# ballast register map
Vendor: tuni.fi; File version: 1.0
CPU: other r1p0, little endian, MPU, no FPU, vendor SysTick, 3 interrupt priority bits
Registers are 32-bit, read-only, no defined reset value unless marked. A register's access mark holds for its fields unless they carry their own. Offsets are from the block's base; [hi:lo] are bit positions; lines under a group give offsets from that group.

## ethernet
Base 0x0E000000
0x00 MAC_registers group
  0x00 Tx_Hwmark rw reset 0x9 (reset mask 0x0) — used to set transmit Fifo high water mark
    [4:0] Tx_Hwmark
  0x04 Tx_Lwmark rw reset 0x8 (reset mask 0x0) — used to set transmit Fifo low water mark
    [4:0] Tx_Lwmark
  0x08 pause_frame_send_en rw — pause_frame_send_en register is used to enable transmit logic to send PAUSE frame.
    [0] pause_frame_send_en
  0x0C pause_quanta_set rw — pause_quanta_set register is used to setting quanta value in send PAUSE frame.
    [15:0] pause_quanta_set
  0x10 IFGset rw reset 0xC (reset mask 0x0) — RX_IFG_SET is used to set received frame gap. If the gap between two received packets is less than RX_IFG_SET,the second packet will be drop as an invalid frame.
    [5:0] IFGset
  0x14 FullDuplex rw reset 0x1 (reset mask 0x0) — This config register is only used in 100Mbps and 10Mbps. When FullDuplex register is equal to “1” , the transmit state machine will be FullDuplex mode. Otherwise, the transmit state machine will detect collision ,perform random slot time back off , retransmit collision packet and some other half-duplex operations.
    [0] FullDuplex
  0x18 MaxRetry rw reset 0x2 (reset mask 0x0) — When collision occurred in half duplex mode, the transmit state machine will try to transmit this collision packet again. If one packet collide MaxRetry times, this packet will be drop and never try again.
    [3:0] MaxRetry
  0x1C MAC_tx_add_en rw — Those registers are used to set mac address which will replace the target mac address of transmit packet. This function will be enable one when register MAC_tx_add_en set to “1”. At the rising edge of signal MAC_tx_add_prom_wr, the value of MAC_tx_add_prom_data will be write to prom address MAC_tx_add_prom_add. You need repeat six times to write six bytes length target mac to prom.
    [0] MAC_tx_add_en
  0x20 MAC_tx_add_prom_data rw — Those registers are used to set mac address which will replace the target mac address of transmit packet. This function will be enable one when register MAC_tx_add_en set to “1”. At the rising edge of signal MAC_tx_add_prom_wr, the value of MAC_tx_add_prom_data will be write to prom address MAC_tx_add_prom_add. You need repeat six times to write six bytes length target mac to prom.
    [7:0] MAC_tx_add_prom_data
  0x24 MAC_tx_add_prom_add rw — Those registers are used to set mac address which will replace the target mac address of transmit packet. This function will be enable one when register MAC_tx_add_en set to “1”. At the rising edge of signal MAC_tx_add_prom_wr, the value of MAC_tx_add_prom_data will be write to prom address MAC_tx_add_prom_add. You need repeat six times to write six bytes length target mac to prom.
    [2:0] MAC_tx_add_prom_add
  0x28 MAC_tx_add_prom_wr rw — Those registers are used to set mac address which will replace the target mac address of transmit packet. This function will be enable one when register MAC_tx_add_en set to “1”. At the rising edge of signal MAC_tx_add_prom_wr, the value of MAC_tx_add_prom_data will be write to prom address MAC_tx_add_prom_add. You need repeat six times to write six bytes length target mac to prom.
    [0] MAC_tx_add_prom_wr
  0x2C tx_pause_en rw — When this register is “1”, this core will respond to received pause frame.The transmit state machine will enter PAUSE state according to quanta value in received packet . One quanta time is equal to the time of transmit 512bit data.
    [0] tx_pause_en
  0x30 xoff_cpu rw — The rising pulse of xoff_cpu signal is used to start transmit one PAUSE frame when the transmit in idle state with quanta zero, asking remote ethernet controller jump out from pause state.
    [0] xoff_cpu
  0x34 xon_cpu rw — The rising pulse of xon_cpu signal is used to start transmit one PAUSE frame with quanta value of pause_quanta_set when the transmit in idle state.
    [0] xon_cpu
  0x38 MAC_rx_add_chk_en rw
    [0] MAC_rx_add_chk_en
  0x3C MAC_rx_add_prom_data rw
    [7:0] MAC_rx_add_prom_data
  0x40 MAC_rx_add_prom_add rw
    [2:0] MAC_rx_add_prom_add
  0x44 MAC_rx_add_prom_wr rw
    [0] MAC_rx_add_prom_wr
  0x48 broadcast_filter_en rw — The broadcast packet filter will enable only when broadcast_filter_en is set
    [0] broadcast_filter_en
  0x4C broadcast_bucket_depth rw — broadcast_bucket_depth register is used to setting the bucket depth
    [15:0] broadcast_bucket_depth
  0x50 broadcast_bucket_interval rw — The bucket wil be periodically refilled after broadcast_bucket_interval time
    [15:0] broadcast_bucket_interval
  0x54 RX_APPEND_CRC rw — In some condition, the user application need MAC to retain FCS of ethernet frame. When RX_APPEND_CRC signal is equal “1” , the FCS of ethernet frame will transmit to user application.
    [0] RX_APPEND_CRC
  0x58 Rx_Hwmark rw reset 0x1A (reset mask 0x0) — used to set receive Fifo high water mark
    [4:0] Rx_Hwmark
  0x5C Rx_Lwmark rw reset 0x10 (reset mask 0x0) — used to set receive Fifo low water mark
    [4:0] Rx_Lwmark
  0x60 CRC_chk_en rw — By default, the receive logic will drop any packet with FCS checksum error. By setting CRC_chk_en register to zero, you can disable received packet FCS checking.
    [0] CRC_chk_en
  0x64 RX_IFG_SET rw reset 0xC (reset mask 0x0) — RX_IFG_SET is used to set received frame gap. If the gap between two received packets is less than RX_IFG_SET,the second packet will be drop as an invalid frame.
    [5:0] RX_IFG_SET
  0x68 RX_MAX_LENGTH rw reset 0x2710 (reset mask 0x0) — The length of Received packet beyond minimal length and maximal length will be droped in receive Fifo. if the packet is already trasmitting in user interface , a error flag will enclosed at end of packet .
    [15:0] RX_MAX_LENGTH
  0x6C RX_MIN_LENGTH rw reset 0x40 (reset mask 0x0) — The length of Received packet beyond minimal length and maximal length will be droped in receive Fifo. if the packet is already trasmitting in user interface , a error flag will enclosed at end of packet .
    [6:0] RX_MIN_LENGTH
  0x70 CPU_rd_addr rw — All statistic counters are stored in a blockram. When you read a counter,you need to write the corresponding address to CPU_rd_addr register and assert CPU_rd_apply signal. When the counter data register CPU_rd_dout is available , the signal CPU_rd_grant will be “1”.
    [5:0] CPU_rd_addr
  0x74 CPU_rd_apply rw — All statistic counters are stored in a blockram. When you read a counter,you need to write the corresponding address to CPU_rd_addr register and assert CPU_rd_apply signal. When the counter data register CPU_rd_dout is available , the signal CPU_rd_grant will be “1”.
    [0] CPU_rd_apply
  0x78 CPU_rd_grant — All statistic counters are stored in a blockram. When you read a counter,you need to write the corresponding address to CPU_rd_addr register and assert CPU_rd_apply signal. When the counter data register CPU_rd_dout is available , the signal CPU_rd_grant will be “1”.
    [0] CPU_rd_grant
  0x7C CPU_rd_dout_l — All statistic counters are stored in a blockram. When you read a counter,you need to write the corresponding address to CPU_rd_addr register and assert CPU_rd_apply signal. When the counter data register CPU_rd_dout is available , the signal CPU_rd_grant will be “1”.
    [15:0] CPU_rd_dout_l
  0x80 CPU_rd_dout_h — All statistic counters are stored in a blockram. When you read a counter,you need to write the corresponding address to CPU_rd_addr register and assert CPU_rd_apply signal. When the counter data register CPU_rd_dout is available , the signal CPU_rd_grant will be “1”.
    [15:0] CPU_rd_dout_h
  0x84 Line_loop_en rw — If Line_loop_en =1 , the packet transmited to Phy will loopback to receive side. This function is used for test purpose.
    [0] Line_loop_en
  0x88 Speed rw reset 0x4 (reset mask 0x0) — This register is used to set speed level of ethernet mac core.
    [2:0] Speed
0x8C MDIO group
  0x00 MDIO_Divider rw reset 0xA (reset mask 0x0) — Acts as input to MDIO clock divider. MDIO clock is derived from Reg_clk (125/2 MHz) by dividing it by this value.
    [7:0] MDIO_Divider
  0x04 MDIO_WrData rw — Data to write over MDIO. Used whenever a write operation is intiated with a write to the MDIO_Ctrl register.
    [15:0] MDIO_WrData
  0x08 MDIO_RegAddr rw — MDIO register address. Used whenever a write or read operation is intiated with a write to the MDIO_Ctrl register.
    [4:0] MDIO_RegAddr
  0x0C MDIO_PhyAddr rw — MDIO PHY address. Used whenever a write or read operation is intiated with a write to the MDIO_Ctrl register
    [4:0] MDIO_PhyAddr
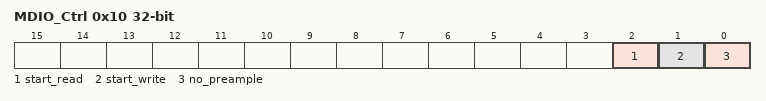
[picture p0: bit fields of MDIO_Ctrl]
  0x10 MDIO_Ctrl rw — Three-bit bitfield. Bit 0 - No Preamble: When this bit is unset, read or write operations start with a 32-bit preamble. When it is set, preamble is not used. Bit 1 - Start Write: When this bit is set, MDIO logic starts a write operation with above write data, PHY and register addresses. This bit is automatically unset when the operation starts. Bit 2 - Start Read: When this bit is set, MDIO logic starts a read operations with above PHY and register addresses. This bit is automatically unset when the operation starts. Bits 1 and 2 should not be set simultaneously.
    [2] start_read — Bit 2 - Start Read: When this bit is set, MDIO logic starts a read operations with above PHY and register addresses. This bit is automatically unset when the operation starts.
    [1] start_write — Bit 1 - Start Write: When this bit is set, MDIO logic starts a write operation with above write data, PHY and register addresses. This bit is automatically unset when the operation starts.
    [0] no_preample — Bit 0 - No Preamble: When this bit is unset, read or write operations start with a 32-bit preamble. When it is set, preamble is not used.
  0x14 MDIO_RdData — After MDIO read transaction has completed, this register is updated with the read result.
    [15:0] MDIO_RdData
  0x18 MDIO_Status — Single-bit register, reads as 1 if MDIO transfer is ongoing.
    [0] MDIO_Status
0x200 DMA_registers group
  0x00 rx_rb_start_address rw — rx_rb_start_address, tx_rb_start_address These registers store the start address for the ring buffer used by the DMA to read from or write to. Writing to these registers has a side effect of initializing the ring buffer from the start address and size registers in the respective DMA unit and resetting the write pointer (for RX) or the read pointer (for TX) to the start of the ring buffer. Therefore, the associated size register (rx_rb_size or tx_rb_size) should be set first. The DMA read and/or write channels remain inactive until the associated ring buffer is initialized by writing to this register.
  0x04 rx_rb_size rw — Stores the ring buffer size for the associated DMA channel in bytes.
  0x08 rx_rb_rd_pointer rw — Stores the read pointers for the ring buffers. For the RX/write channel, the read pointer is maintained by the host processor. If there is a packet available in the MAC RX FIFO but writing it to memory would overwrite unread data -- i.e. advance the write pointer past the read pointer -- The DMA write channel stalls until the read pointer is updated to resolve this conflict. The value should point to the last read address or, when initialized, the last address of the ring buffer. For the TX/read channel, the read pointer register is read-only and maintained by the host processor. The processor must not write “past” the read pointer.
  0x0C rx_pkg_lgth — Data access to the package length FIFO. Length in bytes. rx_pkg_lgth is read-only. The DMA write channel pushes packet lengths to the FIFO after the corresponding AXI transfers for the packet have finished. Reading this register when the associated FIFO is not empty removes the first-written piece of data from the FIFO.
    [15:0] rx_pkg_lgth
  0x10 rx_pkg_lgth_cnt — Read-only register denoting how many packet lengths are available or yet to be processed in the corresponding FIFO.
    [4:0] rx_pkg_lgth_cnt
  0x14 tx_rb_start_addr rw — Register to store the start address for the ring buffer used by the DMA to write to. Writing to the register has a side effect of initializing the ring buffer from the start address and size registers in the respective DMA unit and resetting the write pointer (for RX) to the start of the ring buffer. Therefore, the associated size register (tx_rb_size should be set first The DMA read and/or write channels remain inactive until the associated ring buffer is initialized by writing to this register.
  0x18 tx_rb_size rw — Stores the ring buffer size for the associated DMA channel in bytes.
  0x1C tx_rb_rd_pointer — Stores the read pointers for the ring buffers. For the RX/write channel, the read pointer is maintained by the host processor. If there is a packet available in the MAC RX FIFO but writing it to memory would overwrite unread data -- i.e. advance the write pointer past the read pointer -- The DMA write channel stalls until the read pointer is updated to resolve this conflict. The value should point to the last read address or, when initialized, the last address of the ring buffer. For the TX/read channel, the read pointer register is read-only and maintained by the host processor. The processor must not write “past” the read pointer.
  0x20 tx_pkg_lgth wo — Data access to the package length FIFO. Packet lengths in bytes. tx_pkg_lgth is write-only. To issue a packet to be sent by the MAC, the host processor writes the ethernet frame data to the ring buffer, starting from a 4-byte aligned address immediately after the end of the previous packet, and writes the length of the packet to tx_pkg_lgth, in this order.
    [15:0] tx_pkg_lgth
  0x24 tx_pkg_lgth_cnt — Read-only registers denoting how many packet lengths are available or yet to be processed in the corresponding FIFO.
    [4:0] tx_pkg_lgth_cnt
  0x28 irq rw — One bit corresponds to an interrupt line from the MAC/DMA. When an interrupt is raised and its corresponding bit in irq_mask is set, its corresponding bit in irq is set and the external IRQ line is asserted. The IRQ line is deasserted when all bits in the irq register are unset by a write by the processor. In other words, the external IRQ line is an OR-reduction of the irq register. Writes to the irq register cannot assert new interrupt requests; in other words, the value stored in the irq register is the old contents combined with the write value by a bitwise AND.
    [1:0] irq
  0x2C irq_mask rw
    [1:0] irq_mask
